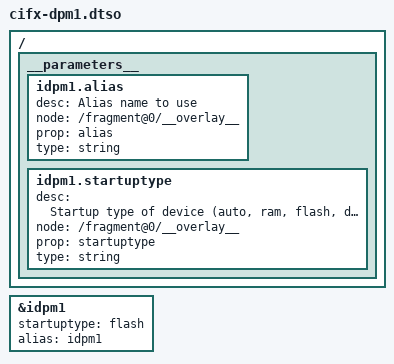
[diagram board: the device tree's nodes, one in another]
/dts-v1/;
/plugin/;

/ {
	fragment@0 {
		target = <&idpm1>;
		__overlay__ {
			status = "okay";
			startuptype = "flash";  /* "auto","ram","flash","donttouch" */
			alias = "idpm1"; /* alias card name */
		};
	};
	__parameters__ {
		idpm1.alias {
			desc = "Alias name to use";
			node = "/fragment@0/__overlay__";
			prop = "alias";
			type = "string";
		};
		idpm1.startuptype {
			desc = "Startup type of device (auto, ram, flash, donttouch)";
			node = "/fragment@0/__overlay__";
			prop = "startuptype";
			type = "string";
		};
	};
};
